# dsPIC33FJ64GS606 register map
Vendor: Microchip; Series: dsPIC33FJ64GS; File version: 1.4.228
Registers are 16-bit, read-write, no defined reset value unless marked. A register's access mark holds for its fields unless they carry their own. Offsets are from the block's base; [hi:lo] are bit positions; {n}, {i} and the like mark numbered series.

## QEI1 — QEI1 peripheral registers
Base 0x000001E0
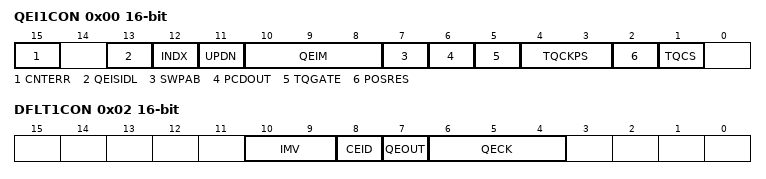
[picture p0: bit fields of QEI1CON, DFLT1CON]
0x00 QEI1CON
  [15] CNTERR — Position count error status flag bit
  [13] QEISIDL — QEI stop in Idle mode bit
  [12] INDX — Index pin state status bit
  [11] UPDN — Position counter direction status bit
  [10:8] QEIM — Quadrature Encoder Interface mode select bits
  [7] SWPAB — Phase A and Phase B input swap select bit
  [6] PCDOUT — Position counter direction state output enable bit
  [5] TQGATE — Timer gated time accumulation enable bit
  [4:3] TQCKPS — Timer input clock prescale select bits
  [2] POSRES — Position counter reset enable bit
  [1] TQCS — Timer clock source select bit
0x02 DFLT1CON
  [10:9] IMV — Index match value bits
  [8] CEID — Count error interrupt disable bit
  [7] QEOUT — Digital filter output enable bit
  [6:4] QECK — Digital filter clock divide select bits
0x04 POS1CNT
  [15:0] POS1CNT — POS1CNT register value
0x06 MAX1CNT
  [15:0] MAX1CNT — MAX1CNT register value

## QEI2 — QEI2 peripheral registers
Base 0x000001F0
Registers as QEI1 (with QEI1 read as QEI2), without DFLT1CON, POS1CNT, MAX1CNT; these are added or differ:
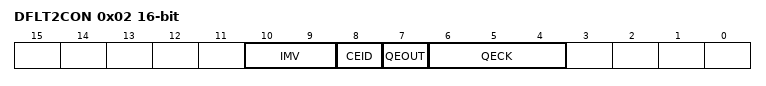
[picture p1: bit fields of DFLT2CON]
0x02 DFLT2CON
  [10:9] IMV — Index match value bits
  [8] CEID — Count error interrupt disable bit
  [7] QEOUT — Digital filter output enable bit
  [6:4] QECK — Digital filter clock divide select bits
0x04 POS2CNT
  [15:0] POS2CNT — POS2CNT register value
0x06 MAX2CNT
  [15:0] MAX2CNT — MAX2CNT register value

## I2C1 — I2C1 peripheral registers
Base 0x00000200
0x00 I2C1RCV
  [15:0] I2C1RCV — I2C1RCV register value
0x02 I2C1TRN
  [15:0] I2C1TRN — I2C1TRN register value
0x04 I2C1BRG
  [15:0] I2C1BRG — I2C1BRG register value
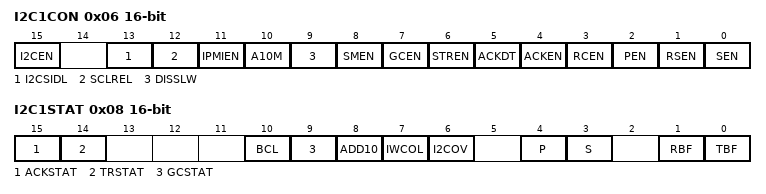
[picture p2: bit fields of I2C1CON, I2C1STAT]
0x06 I2C1CON
  [15] I2CEN — I2C1CON field I2CEN
  [13] I2CSIDL — I2C1CON field I2CSIDL
  [12] SCLREL — I2C1CON field SCLREL
  [11] IPMIEN — I2C1CON field IPMIEN
  [10] A10M — I2C1CON field A10M
  [9] DISSLW — I2C1CON field DISSLW
  [8] SMEN — I2C1CON field SMEN
  [7] GCEN — I2C1CON field GCEN
  [6] STREN — I2C1CON field STREN
  [5] ACKDT — I2C1CON field ACKDT
  [4] ACKEN — I2C1CON field ACKEN
  [3] RCEN — I2C1CON field RCEN
  [2] PEN — I2C1CON field PEN
  [1] RSEN — I2C1CON field RSEN
  [0] SEN — I2C1CON field SEN
0x08 I2C1STAT
  [15] ACKSTAT — I2C1STAT field ACKSTAT
  [14] TRSTAT — I2C1STAT field TRSTAT
  [10] BCL — I2C1STAT field BCL
  [9] GCSTAT — I2C1STAT field GCSTAT
  [8] ADD10 — I2C1STAT field ADD10
  [7] IWCOL — I2C1STAT field IWCOL
  [6] I2COV — I2C1STAT field I2COV
  [4] P — I2C1STAT field P
  [3] S — I2C1STAT field S
  [1] RBF — I2C1STAT field RBF
  [0] TBF — I2C1STAT field TBF
0x0A I2C1ADD
  [15:0] I2C1ADD — I2C1ADD register value
0x0C I2C1MSK
  [15:0] I2C1MSK — I2C1MSK register value

## I2C2 — I2C2 peripheral registers
Base 0x00000210
Registers as I2C1 (with I2C1 read as I2C2).

## UART1 — UART1 peripheral registers
Base 0x00000220
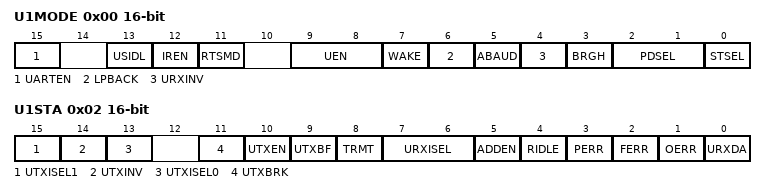
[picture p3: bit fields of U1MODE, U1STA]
0x00 U1MODE
  [15] UARTEN — UART module enable bit
  [13] USIDL — UART stop in Idle mode bit
  [12] IREN — IrDA encoder and decoder enable bit
  [11] RTSMD — RTS pin mode select bit
  [9:8] UEN — UART transmit and receive pin enable bits
  [7] WAKE — Wake-up on Start bit detect enable bit
  [6] LPBACK — Loopback mode select bit
  [5] ABAUD — Auto-baud enable bit
  [4] URXINV — Receive polarity invert bit
  [3] BRGH — High baud rate select bit
  [2:1] PDSEL — Parity and data selection bits
  [0] STSEL — Stop bit selection
0x02 U1STA
  [15] UTXISEL1 — U1STA field UTXISEL1
  [14] UTXINV — Transmit polarity invert bit
  [13] UTXISEL0 — U1STA field UTXISEL0
  [11] UTXBRK — Transmit break bit
  [10] UTXEN — Transmit enable bit
  [9] UTXBF — Transmit buffer full status bit
  [8] TRMT — Transmit shift register empty bit
  [7:6] URXISEL — Receive interrupt mode selection bits
  [5] ADDEN — Address character detect bit
  [4] RIDLE — Receiver Idle bit
  [3] PERR — Parity error status bit
  [2] FERR — Framing error status bit
  [1] OERR — Receive buffer overrun error status bit
  [0] URXDA — Receive buffer data available status bit
0x04 U1TXREG
  [n] UTXREG{n} (n=0..8) — U1TXREG field UTXREG{n}
  [8:0] U1TXREG — U1TXREG field U1TXREG
0x06 U1RXREG
  [n] URXREG{n} (n=0..8) — U1RXREG field URXREG{n}
  [8:0] U1RXREG — U1RXREG field U1RXREG
0x08 U1BRG
  [15:0] U1BRG — U1BRG register value
